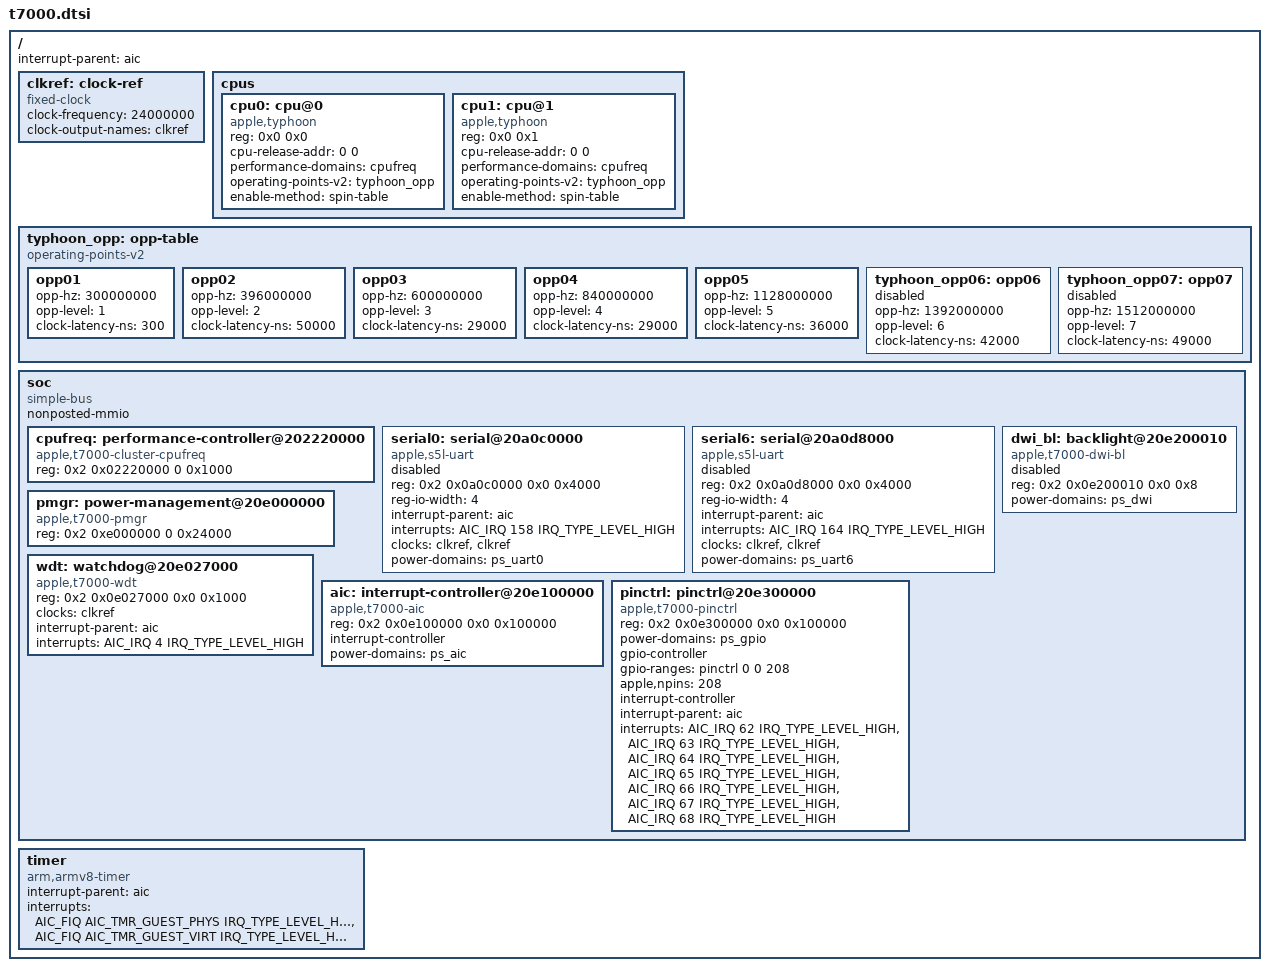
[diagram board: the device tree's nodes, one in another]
// SPDX-License-Identifier: GPL-2.0+ OR MIT
/*
 * Apple T7000 "A8" SoC
 *
 * Other names: H7P, "Fiji"
 *
 * Copyright (c) 2022, Konrad Dybcio <konradybcio@kernel.org>
 * Based on Asahi Linux's M1 (t8103.dtsi) and Corellium's A10 efforts.
 */

#include <dt-bindings/gpio/gpio.h>
#include <dt-bindings/interrupt-controller/apple-aic.h>
#include <dt-bindings/interrupt-controller/irq.h>
#include <dt-bindings/pinctrl/apple.h>

/ {
	interrupt-parent = <&aic>;
	#address-cells = <2>;
	#size-cells = <2>;

	clkref: clock-ref {
		compatible = "fixed-clock";
		#clock-cells = <0>;
		clock-frequency = <24000000>;
		clock-output-names = "clkref";
	};

	cpus {
		#address-cells = <2>;
		#size-cells = <0>;

		cpu0: cpu@0 {
			compatible = "apple,typhoon";
			reg = <0x0 0x0>;
			cpu-release-addr = <0 0>; /* To be filled in by loader */
			performance-domains = <&cpufreq>;
			operating-points-v2 = <&typhoon_opp>;
			enable-method = "spin-table";
			device_type = "cpu";
		};

		cpu1: cpu@1 {
			compatible = "apple,typhoon";
			reg = <0x0 0x1>;
			cpu-release-addr = <0 0>; /* To be filled in by loader */
			performance-domains = <&cpufreq>;
			operating-points-v2 = <&typhoon_opp>;
			enable-method = "spin-table";
			device_type = "cpu";
		};
	};

	typhoon_opp: opp-table {
		compatible = "operating-points-v2";

		opp01 {
			opp-hz = /bits/ 64 <300000000>;
			opp-level = <1>;
			clock-latency-ns = <300>;
		};
		opp02 {
			opp-hz = /bits/ 64 <396000000>;
			opp-level = <2>;
			clock-latency-ns = <50000>;
		};
		opp03 {
			opp-hz = /bits/ 64 <600000000>;
			opp-level = <3>;
			clock-latency-ns = <29000>;
		};
		opp04 {
			opp-hz = /bits/ 64 <840000000>;
			opp-level = <4>;
			clock-latency-ns = <29000>;
		};
		opp05 {
			opp-hz = /bits/ 64 <1128000000>;
			opp-level = <5>;
			clock-latency-ns = <36000>;
		};
		typhoon_opp06: opp06 {
			opp-hz = /bits/ 64 <1392000000>;
			opp-level = <6>;
			clock-latency-ns = <42000>;
			status = "disabled"; /* Not available on N102 */
		};
		typhoon_opp07: opp07 {
			opp-hz = /bits/ 64 <1512000000>;
			opp-level = <7>;
			clock-latency-ns = <49000>;
			status = "disabled"; /* J96 and J97 only */
		};
	};

	soc {
		compatible = "simple-bus";
		#address-cells = <2>;
		#size-cells = <2>;
		nonposted-mmio;
		ranges;

		cpufreq: performance-controller@202220000 {
			compatible = "apple,t7000-cluster-cpufreq", "apple,s5l8960x-cluster-cpufreq";
			reg = <0x2 0x02220000 0 0x1000>;
			#performance-domain-cells = <0>;
		};

		serial0: serial@20a0c0000 {
			compatible = "apple,s5l-uart";
			reg = <0x2 0x0a0c0000 0x0 0x4000>;
			reg-io-width = <4>;
			interrupt-parent = <&aic>;
			interrupts = <AIC_IRQ 158 IRQ_TYPE_LEVEL_HIGH>;
			/* Use the bootloader-enabled clocks for now. */
			clocks = <&clkref>, <&clkref>;
			clock-names = "uart", "clk_uart_baud0";
			power-domains = <&ps_uart0>;
			status = "disabled";
		};

		serial6: serial@20a0d8000 {
			compatible = "apple,s5l-uart";
			reg = <0x2 0x0a0d8000 0x0 0x4000>;
			reg-io-width = <4>;
			interrupt-parent = <&aic>;
			interrupts = <AIC_IRQ 164 IRQ_TYPE_LEVEL_HIGH>;
			/* Use the bootloader-enabled clocks for now. */
			clocks = <&clkref>, <&clkref>;
			clock-names = "uart", "clk_uart_baud0";
			power-domains = <&ps_uart6>;
			status = "disabled";
		};

		pmgr: power-management@20e000000 {
			compatible = "apple,t7000-pmgr", "apple,pmgr", "syscon", "simple-mfd";
			#address-cells = <1>;
			#size-cells = <1>;

			reg = <0x2 0xe000000 0 0x24000>;
		};

		wdt: watchdog@20e027000 {
			compatible = "apple,t7000-wdt", "apple,wdt";
			reg = <0x2 0x0e027000 0x0 0x1000>;
			clocks = <&clkref>;
			interrupt-parent = <&aic>;
			interrupts = <AIC_IRQ 4 IRQ_TYPE_LEVEL_HIGH>;
		};

		aic: interrupt-controller@20e100000 {
			compatible = "apple,t7000-aic", "apple,aic";
			reg = <0x2 0x0e100000 0x0 0x100000>;
			#interrupt-cells = <3>;
			interrupt-controller;
			power-domains = <&ps_aic>;
		};

		dwi_bl: backlight@20e200010 {
			compatible = "apple,t7000-dwi-bl", "apple,dwi-bl";
			reg = <0x2 0x0e200010 0x0 0x8>;
			power-domains = <&ps_dwi>;
			status = "disabled";
		};

		pinctrl: pinctrl@20e300000 {
			compatible = "apple,t7000-pinctrl", "apple,pinctrl";
			reg = <0x2 0x0e300000 0x0 0x100000>;
			power-domains = <&ps_gpio>;

			gpio-controller;
			#gpio-cells = <2>;
			gpio-ranges = <&pinctrl 0 0 208>;
			apple,npins = <208>;

			interrupt-controller;
			#interrupt-cells = <2>;
			interrupt-parent = <&aic>;
			interrupts = <AIC_IRQ 62 IRQ_TYPE_LEVEL_HIGH>,
				     <AIC_IRQ 63 IRQ_TYPE_LEVEL_HIGH>,
				     <AIC_IRQ 64 IRQ_TYPE_LEVEL_HIGH>,
				     <AIC_IRQ 65 IRQ_TYPE_LEVEL_HIGH>,
				     <AIC_IRQ 66 IRQ_TYPE_LEVEL_HIGH>,
				     <AIC_IRQ 67 IRQ_TYPE_LEVEL_HIGH>,
				     <AIC_IRQ 68 IRQ_TYPE_LEVEL_HIGH>;
		};
	};

	timer {
		compatible = "arm,armv8-timer";
		interrupt-parent = <&aic>;
		interrupt-names = "phys", "virt";
		/* Note that A8 doesn't actually have a hypervisor (EL2 is not implemented). */
		interrupts = <AIC_FIQ AIC_TMR_GUEST_PHYS IRQ_TYPE_LEVEL_HIGH>,
			     <AIC_FIQ AIC_TMR_GUEST_VIRT IRQ_TYPE_LEVEL_HIGH>;
	};
};

#include "t7000-pmgr.dtsi"
